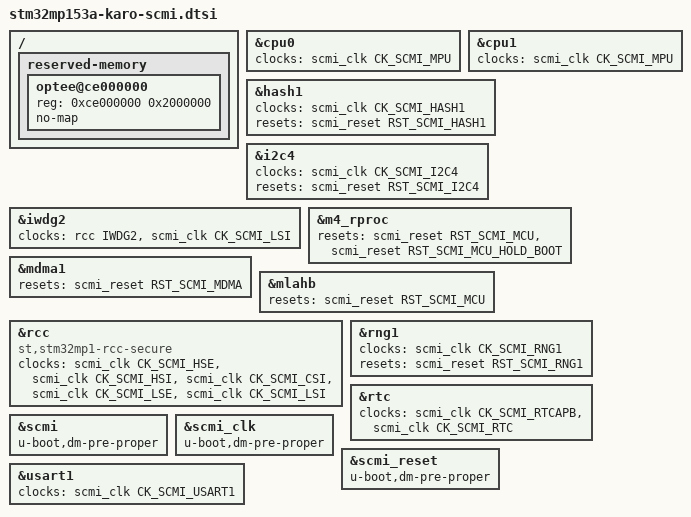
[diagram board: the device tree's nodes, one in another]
// SPDX-License-Identifier: (GPL-2.0-or-later OR BSD-3-Clause)
/*
 * Copyright (C) STMicroelectronics 2022 - All Rights Reserved
 * Author: Alexandre Torgue <alexandre.torgue@foss.st.com> for STMicroelectronics.
 */

#include "stm32mp15-scmi.dtsi"
#include "stm32mp15xa.dtsi"

/ {
	reserved-memory {
		optee@ce000000 {
			reg = <0xce000000 0x2000000>;
			no-map;
		};
	};
};

&cpu0 {
	clocks = <&scmi_clk CK_SCMI_MPU>;
};

&cpu1 {
	clocks = <&scmi_clk CK_SCMI_MPU>;
};

&hash1 {
	clocks = <&scmi_clk CK_SCMI_HASH1>;
	resets = <&scmi_reset RST_SCMI_HASH1>;
};

&i2c4 {
	clocks = <&scmi_clk CK_SCMI_I2C4>;
	resets = <&scmi_reset RST_SCMI_I2C4>;
};

&iwdg2 {
	clocks = <&rcc IWDG2>, <&scmi_clk CK_SCMI_LSI>;
};

&m4_rproc {
	resets = <&scmi_reset RST_SCMI_MCU>,
		 <&scmi_reset RST_SCMI_MCU_HOLD_BOOT>;
	reset-names = "mcu_rst", "hold_boot";
	/delete-property/ st,syscfg-holdboot;
};

&mdma1 {
	resets = <&scmi_reset RST_SCMI_MDMA>;
};

&mlahb {
	resets = <&scmi_reset RST_SCMI_MCU>;
};

&rcc {
	compatible = "st,stm32mp1-rcc-secure", "syscon";
	clock-names = "hse", "hsi", "csi", "lse", "lsi";
	clocks = <&scmi_clk CK_SCMI_HSE>,
		 <&scmi_clk CK_SCMI_HSI>,
		 <&scmi_clk CK_SCMI_CSI>,
		 <&scmi_clk CK_SCMI_LSE>,
		 <&scmi_clk CK_SCMI_LSI>;
};

&rng1 {
	clocks = <&scmi_clk CK_SCMI_RNG1>;
	resets = <&scmi_reset RST_SCMI_RNG1>;
};

&rtc {
	clocks = <&scmi_clk CK_SCMI_RTCAPB>, <&scmi_clk CK_SCMI_RTC>;
};

&scmi {
	u-boot,dm-pre-proper;
};

&scmi_clk {
	u-boot,dm-pre-proper;
};

&scmi_reset {
	u-boot,dm-pre-proper;
};

&usart1 {
	clocks = <&scmi_clk CK_SCMI_USART1>;
};
